AUTOSAR XML (schema 4-2-2)
package /ComponentTypes
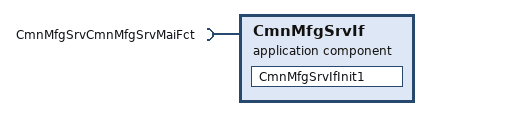
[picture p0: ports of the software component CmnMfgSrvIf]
  application sw component type CmnMfgSrvIf
    require port CmnMfgSrvCmnMfgSrvMaiFct: client-com-spec=Oper, required-interface=CmnMfgSrvCmnMfgSrvMaiFct
    behavior CmnMfgSrvIf_InternalBehavior
      init event CmnMfgSrvIf_InitEvent: start-on-event=CmnMfgSrvIfInit1
      runnable CmnMfgSrvIfInit1
        sync call SC_CmnMfgSrvCmnMfgSrvMaiFct_Oper: operation=CmnMfgSrvCmnMfgSrvMaiFct.Oper, timeout=0
  swc implementation CmnMfgSrvIf_Implementation: behavior=CmnMfgSrvIf_InternalBehavior
    code-descriptors:
      code Default: artifact-descriptors=autosar-engineering-object={short-label=Default, category=SWSRC}
